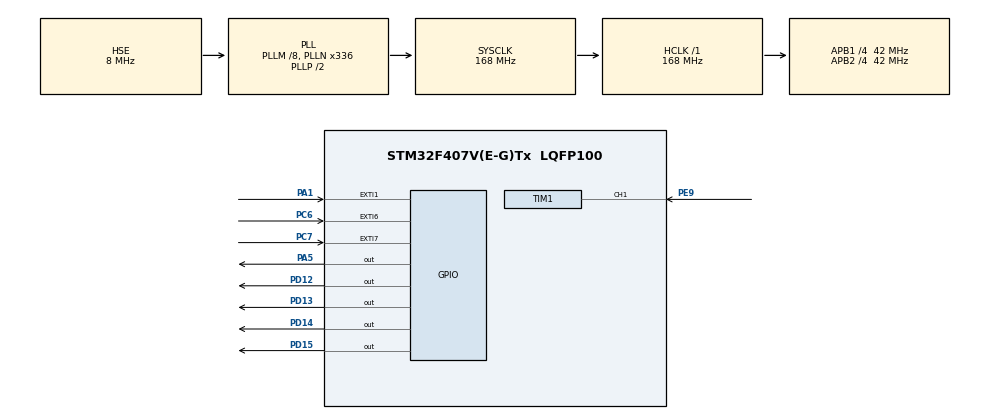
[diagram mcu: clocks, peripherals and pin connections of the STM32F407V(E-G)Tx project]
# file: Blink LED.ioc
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Mcu.Family=STM32F4
Mcu.Name=STM32F407V(E-G)Tx
Mcu.Package=LQFP100
NVIC.EXTI1_IRQn=true\:0\:0\:false\:false\:true\:true\:true\:true
NVIC.EXTI9_5_IRQn=true\:0\:0\:false\:false\:true\:true\:true\:true
NVIC.PriorityGroup=NVIC_PRIORITYGROUP_4
PA1.Signal=GPXTI1
PA5.Signal=GPIO_Output
PC6.Signal=GPXTI6
PC7.Signal=GPXTI7
PD12.GPIO_ModeDefaultOutputPP=GPIO_MODE_OUTPUT_PP
PD12.GPIO_PuPd=GPIO_NOPULL
PD12.GPIO_Speed=GPIO_SPEED_FREQ_VERY_HIGH
PD12.PinState=GPIO_PIN_SET
PD12.Signal=GPIO_Output
PD13.GPIO_ModeDefaultOutputPP=GPIO_MODE_OUTPUT_PP
PD13.GPIO_PuPd=GPIO_NOPULL
PD13.GPIO_Speed=GPIO_SPEED_FREQ_VERY_HIGH
PD13.PinState=GPIO_PIN_SET
PD13.Signal=GPIO_Output
PD14.GPIO_ModeDefaultOutputPP=GPIO_MODE_OUTPUT_PP
PD14.GPIO_PuPd=GPIO_NOPULL
PD14.GPIO_Speed=GPIO_SPEED_FREQ_VERY_HIGH
PD14.PinState=GPIO_PIN_SET
PD14.Signal=GPIO_Output
PD15.GPIO_ModeDefaultOutputPP=GPIO_MODE_OUTPUT_PP
PD15.GPIO_PuPd=GPIO_NOPULL
PD15.GPIO_Speed=GPIO_SPEED_FREQ_VERY_HIGH
PD15.PinState=GPIO_PIN_SET
PD15.Signal=GPIO_Output
PE9.Signal=S_TIM1_CH1
PH0-OSC_IN.Mode=HSE-External-Oscillator
PH0-OSC_IN.Signal=RCC_OSC_IN
PH1-OSC_OUT.Mode=HSE-External-Oscillator
PH1-OSC_OUT.Signal=RCC_OSC_OUT
ProjectManager.HeapSize=0x200
ProjectManager.StackSize=0x400
ProjectManager.TargetToolchain=MDK-ARM V5.32
RCC.48MHZClocksFreq_Value=84000000
RCC.AHBFreq_Value=168000000
RCC.APB1CLKDivider=RCC_HCLK_DIV4
RCC.APB1Freq_Value=42000000
RCC.APB1TimFreq_Value=84000000
RCC.APB2CLKDivider=RCC_HCLK_DIV4
RCC.APB2Freq_Value=42000000
RCC.APB2TimFreq_Value=84000000
RCC.CortexFreq_Value=168000000
RCC.HCLKFreq_Value=168000000
RCC.HSE_VALUE=8000000
RCC.HSI_VALUE=16000000
RCC.LSE_VALUE=32768
RCC.PLLM=8
RCC.PLLN=336
RCC.PLLSourceVirtual=RCC_PLLSOURCE_HSE
RCC.SYSCLKFreq_VALUE=168000000
RCC.SYSCLKSource=RCC_SYSCLKSOURCE_PLLCLK
RCC.VCOOutputFreq_Value=336000000
SH.S_TIM1_CH1.0=TIM1_CH1,Input_Capture1_from_TI1
TIM1.Channel-Input_Capture1_from_TI1=TIM_CHANNEL_1
TIM1.Prescaler=168-1
board=Blink LED

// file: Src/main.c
/* USER CODE BEGIN Header */
/**
  ******************************************************************************
  * @file           : main.c
  * @brief          : Main program body
  ******************************************************************************
  * @attention
  *
  * Copyright (c) 2022 STMicroelectronics.
  * All rights reserved.
  *
  * This software is licensed under terms that can be found in the LICENSE file
  * in the root directory of this software component.
  * If no LICENSE file comes with this software, it is provided AS-IS.
  *
  ******************************************************************************
  */
/* USER CODE END Header */
#include "main.h"

 TIM_HandleTypeDef htim1;

void SystemClock_Config(void);
static void MX_GPIO_Init(void);
static void MX_TIM1_Init(void);

/* USER CODE BEGIN 0 */
volatile uint32_t IC_Val1, IC_Val2, Difference;
// is the first value captured ?
volatile uint8_t Is_First_Captured, Distance;

#define TRIG_PIN GPIO_PIN_5
#define TRIG_PORT GPIOA
/* USER CODE END 0 */

int main(void)
{

  /* MCU Configuration--------------------------------------------------------*/

  /* Reset of all peripherals, Initializes the Flash interface and the Systick. */
  HAL_Init();

  /* Configure the system clock */
  SystemClock_Config();

  /* Initialize all configured peripherals */
  MX_GPIO_Init();
  MX_TIM1_Init();
  /* USER CODE BEGIN 2 */
	HAL_TIM_IC_Start_IT(&htim1, TIM_CHANNEL_1);
  /* USER CODE END 2 */

  /* Infinite loop */
  /* USER CODE BEGIN WHILE */
  while (1)
  {
	HAL_Delay(800);  // wait for 10 us
    /* USER CODE END WHILE */
	HAL_GPIO_WritePin(TRIG_PORT, TRIG_PIN, GPIO_PIN_SET);  // pull the TRIG pin HIGH
	HAL_Delay(10);  // wait for 10 us
	HAL_GPIO_WritePin(TRIG_PORT, TRIG_PIN, GPIO_PIN_RESET);  // pull the TRIG pin low

	__HAL_TIM_ENABLE_IT(&htim1, TIM_IT_CC1);
  }
}

uint8_t input_capture_cnt;
void HAL_TIM_IC_CaptureCallback(TIM_HandleTypeDef *htim)
{
	if (htim->Channel == HAL_TIM_ACTIVE_CHANNEL_1)  // if the interrupt source is channel1
	{
		input_capture_cnt++;
		if (Is_First_Captured==0) // if the first value is not captured
		{
			IC_Val1 = HAL_TIM_ReadCapturedValue(htim, TIM_CHANNEL_1); // read the first value
			Is_First_Captured = 1;  // set the first captured as true
			// Now change the polarity to falling edge
			__HAL_TIM_SET_CAPTUREPOLARITY(htim, TIM_CHANNEL_1, TIM_INPUTCHANNELPOLARITY_FALLING);
		}

		else if (Is_First_Captured==1)   // if the first is already captured
		{
			IC_Val2 = HAL_TIM_ReadCapturedValue(htim, TIM_CHANNEL_1);  // read second value
			__HAL_TIM_SET_COUNTER(htim, 0);  // reset the counter

			if (IC_Val2 > IC_Val1)
			{
				Difference = IC_Val2-IC_Val1;
			}

			else if (IC_Val1 > IC_Val2)
			{
				Difference = (0xffff - IC_Val1) + IC_Val2;
			}

			Distance = Difference * .034/2;
			Is_First_Captured = 0; // set it back to false

			// set polarity to rising edge
			__HAL_TIM_SET_CAPTUREPOLARITY(htim, TIM_CHANNEL_1, TIM_INPUTCHANNELPOLARITY_RISING);
			__HAL_TIM_DISABLE_IT(&htim1, TIM_IT_CC1);
		}
	}
}

void SystemClock_Config(void)
{
  RCC_OscInitTypeDef RCC_OscInitStruct = {0};
  RCC_ClkInitTypeDef RCC_ClkInitStruct = {0};

  /** Configure the main internal regulator output voltage
  */
  __HAL_RCC_PWR_CLK_ENABLE();
  __HAL_PWR_VOLTAGESCALING_CONFIG(PWR_REGULATOR_VOLTAGE_SCALE1);

  /** Initializes the RCC Oscillators according to the specified parameters
  * in the RCC_OscInitTypeDef structure.
  */
  RCC_OscInitStruct.OscillatorType = RCC_OSCILLATORTYPE_HSE;
  RCC_OscInitStruct.HSEState = RCC_HSE_ON;
  RCC_OscInitStruct.PLL.PLLState = RCC_PLL_ON;
  RCC_OscInitStruct.PLL.PLLSource = RCC_PLLSOURCE_HSE;
  RCC_OscInitStruct.PLL.PLLM = 8;
  RCC_OscInitStruct.PLL.PLLN = 336;
  RCC_OscInitStruct.PLL.PLLP = RCC_PLLP_DIV2;
  RCC_OscInitStruct.PLL.PLLQ = 4;
  if (HAL_RCC_OscConfig(&RCC_OscInitStruct) != HAL_OK)
  {
    Error_Handler();
  }

  /** Initializes the CPU, AHB and APB buses clocks
  */
  RCC_ClkInitStruct.ClockType = RCC_CLOCKTYPE_HCLK|RCC_CLOCKTYPE_SYSCLK
                              |RCC_CLOCKTYPE_PCLK1|RCC_CLOCKTYPE_PCLK2;
  RCC_ClkInitStruct.SYSCLKSource = RCC_SYSCLKSOURCE_PLLCLK;
  RCC_ClkInitStruct.AHBCLKDivider = RCC_SYSCLK_DIV1;
  RCC_ClkInitStruct.APB1CLKDivider = RCC_HCLK_DIV4;
  RCC_ClkInitStruct.APB2CLKDivider = RCC_HCLK_DIV4;

  if (HAL_RCC_ClockConfig(&RCC_ClkInitStruct, FLASH_LATENCY_5) != HAL_OK)
  {
    Error_Handler();
  }
}

static void MX_TIM1_Init(void)
{

  TIM_MasterConfigTypeDef sMasterConfig = {0};
  TIM_IC_InitTypeDef sConfigIC = {0};

  htim1.Instance = TIM1;
  htim1.Init.Prescaler = 168-1;
  htim1.Init.CounterMode = TIM_COUNTERMODE_UP;
  htim1.Init.Period = 65535;
  htim1.Init.ClockDivision = TIM_CLOCKDIVISION_DIV1;
  htim1.Init.RepetitionCounter = 0;
  htim1.Init.AutoReloadPreload = TIM_AUTORELOAD_PRELOAD_DISABLE;
  if (HAL_TIM_IC_Init(&htim1) != HAL_OK)
  {
    Error_Handler();
  }
  sMasterConfig.MasterOutputTrigger = TIM_TRGO_RESET;
  sMasterConfig.MasterSlaveMode = TIM_MASTERSLAVEMODE_DISABLE;
  if (HAL_TIMEx_MasterConfigSynchronization(&htim1, &sMasterConfig) != HAL_OK)
  {
    Error_Handler();
  }
  sConfigIC.ICPolarity = TIM_INPUTCHANNELPOLARITY_RISING;
  sConfigIC.ICSelection = TIM_ICSELECTION_DIRECTTI;
  sConfigIC.ICPrescaler = TIM_ICPSC_DIV1;
  sConfigIC.ICFilter = 0;
  if (HAL_TIM_IC_ConfigChannel(&htim1, &sConfigIC, TIM_CHANNEL_1) != HAL_OK)
  {
    Error_Handler();
  }

}

static void MX_GPIO_Init(void)
{
  GPIO_InitTypeDef GPIO_InitStruct = {0};

  /* GPIO Ports Clock Enable */
  __HAL_RCC_GPIOH_CLK_ENABLE();
  __HAL_RCC_GPIOA_CLK_ENABLE();
  __HAL_RCC_GPIOE_CLK_ENABLE();
  __HAL_RCC_GPIOD_CLK_ENABLE();
  __HAL_RCC_GPIOC_CLK_ENABLE();

  /*Configure GPIO pin Output Level */
  HAL_GPIO_WritePin(GPIOA, GPIO_PIN_5, GPIO_PIN_RESET);

  /*Configure GPIO pin Output Level */
  HAL_GPIO_WritePin(GPIOD, GPIO_PIN_12|GPIO_PIN_13|GPIO_PIN_14|GPIO_PIN_15, GPIO_PIN_SET);

  /*Configure GPIO pin : PA1 */
  GPIO_InitStruct.Pin = GPIO_PIN_1;
  GPIO_InitStruct.Mode = GPIO_MODE_IT_RISING;
  GPIO_InitStruct.Pull = GPIO_NOPULL;
  HAL_GPIO_Init(GPIOA, &GPIO_InitStruct);

  /*Configure GPIO pin : PA5 */
  GPIO_InitStruct.Pin = GPIO_PIN_5;
  GPIO_InitStruct.Mode = GPIO_MODE_OUTPUT_PP;
  GPIO_InitStruct.Pull = GPIO_NOPULL;
  GPIO_InitStruct.Speed = GPIO_SPEED_FREQ_LOW;
  HAL_GPIO_Init(GPIOA, &GPIO_InitStruct);

  /*Configure GPIO pins : PD12 PD13 PD14 PD15 */
  GPIO_InitStruct.Pin = GPIO_PIN_12|GPIO_PIN_13|GPIO_PIN_14|GPIO_PIN_15;
  GPIO_InitStruct.Mode = GPIO_MODE_OUTPUT_PP;
  GPIO_InitStruct.Pull = GPIO_NOPULL;
  GPIO_InitStruct.Speed = GPIO_SPEED_FREQ_VERY_HIGH;
  HAL_GPIO_Init(GPIOD, &GPIO_InitStruct);

  /*Configure GPIO pins : PC6 PC7 */
  GPIO_InitStruct.Pin = GPIO_PIN_6|GPIO_PIN_7;
  GPIO_InitStruct.Mode = GPIO_MODE_IT_RISING;
  GPIO_InitStruct.Pull = GPIO_NOPULL;
  HAL_GPIO_Init(GPIOC, &GPIO_InitStruct);

  /* EXTI interrupt init*/
  HAL_NVIC_SetPriority(EXTI1_IRQn, 0, 0);
  HAL_NVIC_EnableIRQ(EXTI1_IRQn);

  HAL_NVIC_SetPriority(EXTI9_5_IRQn, 0, 0);
  HAL_NVIC_EnableIRQ(EXTI9_5_IRQn);

}

void Error_Handler(void)
{
  __disable_irq();
  while (1)
  {
  }
}
